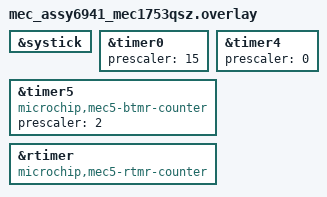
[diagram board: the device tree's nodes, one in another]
/* To test the counter driver for MCHP RTOS timer and basic timer 5
 * we must switch rtimer to use the counter driver which requires
 * switching kernel to use ARM SysTick.
 */
&systick {
	status = "okay";
};

/* 16-bit basic timer 0 at 24 MHz
 * Test program uses 20,000 ticks for many test which
 * exceeds 16-bits at frequencies above 3 MHz.
 * Set prescaler to 15 for a divider of 16 = 3 MHz.
 */
&timer0 {
	status = "okay";
	prescaler = <15>;
};

/* 32-bit basic timer */
&timer4 {
	status = "okay";
	prescaler = <0>;
};

/* 32-bit basic timer 5 at 48 / (2+1) = 16 MHz */
&timer5 {
	compatible = "microchip,mec5-btmr-counter";
	status = "okay";
	prescaler = <2>;
};

/* 32 KHz RTOS 32-bit timer */
&rtimer {
	compatible = "microchip,mec5-rtmr-counter";
	status = "okay";
};
